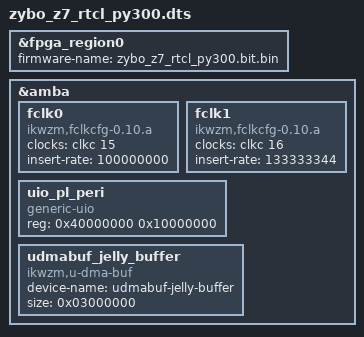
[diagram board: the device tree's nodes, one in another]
/dts-v1/; /plugin/;

/ {
    fragment@0 {  
        target = <&fpga_region0>;
        __overlay__ {
            #address-cells = <1>;
            #size-cells = <1>;

            firmware-name = "zybo_z7_rtcl_py300.bit.bin";
        };
    };

    fragment@1 {
        target = <&amba>;
        __overlay__ {
            fclk0 {
                compatible  = "ikwzm,fclkcfg-0.10.a";
                clocks      = <&clkc 15>;
                insert-rate = "100000000";
            };
            fclk1 {
                compatible  = "ikwzm,fclkcfg-0.10.a";
                clocks      = <&clkc 16>;
                insert-rate = "133333344";
            };
        };
    };

    fragment@2 {
        target = <&amba>;
        __overlay__ {
            #address-cells = <0x1>;
            #size-cells = <0x1>;
            
            uio_pl_peri {
                compatible = "generic-uio";
                reg = <0x40000000 0x10000000>;
            };

            udmabuf_jelly_buffer {
                compatible = "ikwzm,u-dma-buf";
                device-name = "udmabuf-jelly-buffer";
                size = <0x03000000>;
            };
        };
    };

    /*
    fragment@3 {
        target = <&i2c0>;
        __overlay__ {
            status = "okay";
        };
    };
    */

    /*
    fragment@3 {
//      target-path = "/amba";
        target = <&amba>;
        __overlay__ {
    		i2c@e0004000 {
                compatible = "cdns,i2c-r1p10";
                status = "okay";
                clocks = <0x1 0x26>;
                interrupt-parent = <0x4>;
                interrupts = <0x0 0x19 0x4>;
                reg = <0xe0004000 0x1000>;
                #address-cells = <0x1>;
                #size-cells = <0x0>;
            };
		};
    };
    */
};


